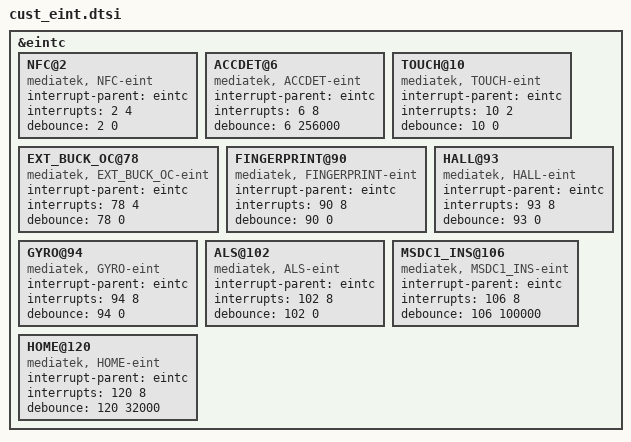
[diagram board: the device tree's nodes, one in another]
/*
 * Generated by MTK SP DrvGen Version 03.13.6 for MT6735M. Copyright MediaTek Inc. (C) 2013.
 * Tue Nov 08 15:41:43 2016
 * Do Not Modify the File.
 */

/*************************
 * EINT DTSI File
*************************/

&eintc {
	NFC@2 {
		compatible = "mediatek, NFC-eint";
		interrupt-parent = <&eintc>;
		interrupts = <2 4>;
		debounce = <2 0>;
	};

	ACCDET@6 {
		compatible = "mediatek, ACCDET-eint";
		interrupt-parent = <&eintc>;
		interrupts = <6 8>;
		debounce = <6 256000>;
	};

	TOUCH@10 {
		compatible = "mediatek, TOUCH-eint";
		interrupt-parent = <&eintc>;
		interrupts = <10 2>;
		debounce = <10 0>;
	};

	EXT_BUCK_OC@78 {
		compatible = "mediatek, EXT_BUCK_OC-eint";
		interrupt-parent = <&eintc>;
		interrupts = <78 4>;
		debounce = <78 0>;
	};

	FINGERPRINT@90 {
		compatible = "mediatek, FINGERPRINT-eint";
		interrupt-parent = <&eintc>;
		interrupts = <90 8>;
		debounce = <90 0>;
	};

	HALL@93 {
		compatible = "mediatek, HALL-eint";
		interrupt-parent = <&eintc>;
		interrupts = <93 8>;
		debounce = <93 0>;
	};

	GYRO@94 {
		compatible = "mediatek, GYRO-eint";
		interrupt-parent = <&eintc>;
		interrupts = <94 8>;
		debounce = <94 0>;
	};

	ALS@102 {
		compatible = "mediatek, ALS-eint";
		interrupt-parent = <&eintc>;
		interrupts = <102 8>;
		debounce = <102 0>;
	};

	MSDC1_INS@106 {
		compatible = "mediatek, MSDC1_INS-eint";
		interrupt-parent = <&eintc>;
		interrupts = <106 8>;
		debounce = <106 100000>;
	};

	HOME@120 {
		compatible = "mediatek, HOME-eint";
		interrupt-parent = <&eintc>;
		interrupts = <120 8>;
		debounce = <120 32000>;
	};

};
